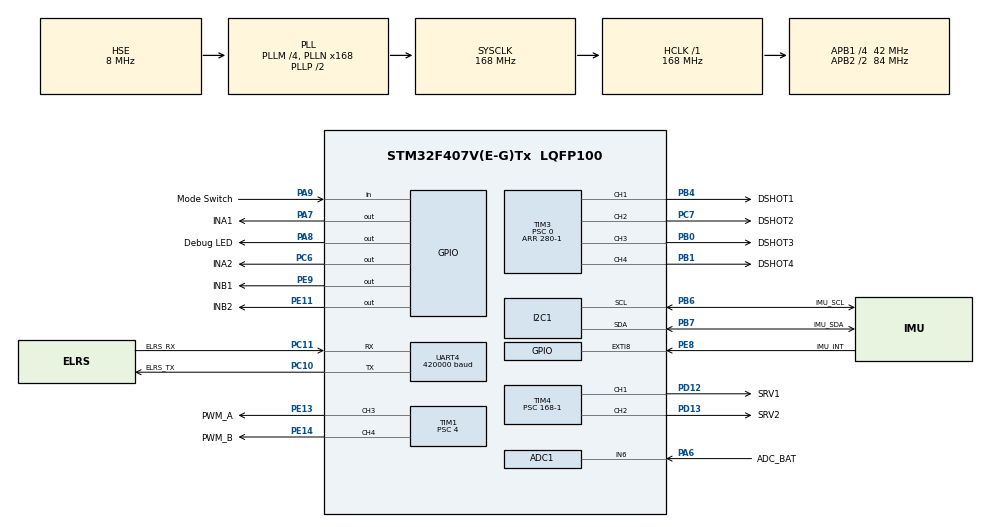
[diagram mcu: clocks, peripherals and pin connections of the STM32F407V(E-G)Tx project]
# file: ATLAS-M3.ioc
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ADC1.Channel-3\#ChannelRegularConversion=ADC_CHANNEL_6
ADC1.ClockPrescaler=ADC_CLOCK_SYNC_PCLK_DIV4
ADC1.ContinuousConvMode=ENABLE
ADC1.DMAContinuousRequests=ENABLE
ADC1.NbrOfConversion=1
ADC1.NbrOfConversionFlag=1
ADC1.Rank-3\#ChannelRegularConversion=1
ADC1.SamplingTime-3\#ChannelRegularConversion=ADC_SAMPLETIME_144CYCLES
ADC1.master=1
Dma.ADC1.0.Direction=DMA_PERIPH_TO_MEMORY
Dma.ADC1.0.FIFOMode=DMA_FIFOMODE_DISABLE
Dma.ADC1.0.Instance=DMA2_Stream0
Dma.ADC1.0.MemDataAlignment=DMA_MDATAALIGN_HALFWORD
Dma.ADC1.0.MemInc=DMA_MINC_ENABLE
Dma.ADC1.0.Mode=DMA_CIRCULAR
Dma.ADC1.0.PeriphDataAlignment=DMA_PDATAALIGN_HALFWORD
Dma.ADC1.0.PeriphInc=DMA_PINC_DISABLE
Dma.ADC1.0.Priority=DMA_PRIORITY_LOW
Dma.Request0=ADC1
Dma.Request1=TIM3_CH1/TRIG
Dma.Request2=TIM3_CH2
Dma.Request3=TIM3_CH3
Dma.Request4=TIM3_CH4/UP
Dma.TIM3_CH1/TRIG.1.Direction=DMA_MEMORY_TO_PERIPH
Dma.TIM3_CH1/TRIG.1.FIFOMode=DMA_FIFOMODE_DISABLE
Dma.TIM3_CH1/TRIG.1.Instance=DMA1_Stream4
Dma.TIM3_CH1/TRIG.1.MemDataAlignment=DMA_MDATAALIGN_HALFWORD
Dma.TIM3_CH1/TRIG.1.MemInc=DMA_MINC_ENABLE
Dma.TIM3_CH1/TRIG.1.Mode=DMA_NORMAL
Dma.TIM3_CH1/TRIG.1.PeriphDataAlignment=DMA_PDATAALIGN_HALFWORD
Dma.TIM3_CH1/TRIG.1.PeriphInc=DMA_PINC_DISABLE
Dma.TIM3_CH1/TRIG.1.Priority=DMA_PRIORITY_HIGH
Dma.TIM3_CH2.2.Direction=DMA_MEMORY_TO_PERIPH
Dma.TIM3_CH2.2.FIFOMode=DMA_FIFOMODE_DISABLE
Dma.TIM3_CH2.2.Instance=DMA1_Stream5
Dma.TIM3_CH2.2.MemDataAlignment=DMA_MDATAALIGN_HALFWORD
Dma.TIM3_CH2.2.MemInc=DMA_MINC_ENABLE
Dma.TIM3_CH2.2.Mode=DMA_NORMAL
Dma.TIM3_CH2.2.PeriphDataAlignment=DMA_PDATAALIGN_HALFWORD
Dma.TIM3_CH2.2.PeriphInc=DMA_PINC_DISABLE
Dma.TIM3_CH2.2.Priority=DMA_PRIORITY_HIGH
Dma.TIM3_CH3.3.Direction=DMA_MEMORY_TO_PERIPH
Dma.TIM3_CH3.3.FIFOMode=DMA_FIFOMODE_DISABLE
Dma.TIM3_CH3.3.Instance=DMA1_Stream7
Dma.TIM3_CH3.3.MemDataAlignment=DMA_MDATAALIGN_HALFWORD
Dma.TIM3_CH3.3.MemInc=DMA_MINC_ENABLE
Dma.TIM3_CH3.3.Mode=DMA_NORMAL
Dma.TIM3_CH3.3.PeriphDataAlignment=DMA_PDATAALIGN_HALFWORD
Dma.TIM3_CH3.3.PeriphInc=DMA_PINC_DISABLE
Dma.TIM3_CH3.3.Priority=DMA_PRIORITY_HIGH
Dma.TIM3_CH4/UP.4.Direction=DMA_MEMORY_TO_PERIPH
Dma.TIM3_CH4/UP.4.FIFOMode=DMA_FIFOMODE_DISABLE
Dma.TIM3_CH4/UP.4.Instance=DMA1_Stream2
Dma.TIM3_CH4/UP.4.MemDataAlignment=DMA_MDATAALIGN_HALFWORD
Dma.TIM3_CH4/UP.4.MemInc=DMA_MINC_ENABLE
Dma.TIM3_CH4/UP.4.Mode=DMA_NORMAL
Dma.TIM3_CH4/UP.4.PeriphDataAlignment=DMA_PDATAALIGN_HALFWORD
Dma.TIM3_CH4/UP.4.PeriphInc=DMA_PINC_DISABLE
Dma.TIM3_CH4/UP.4.Priority=DMA_PRIORITY_HIGH
I2C1.I2C_Mode=I2C_Standard
Mcu.Family=STM32F4
Mcu.Name=STM32F407V(E-G)Tx
Mcu.Package=LQFP100
NVIC.DMA1_Stream2_IRQn=true\:3\:0\:true\:false\:true\:false\:true\:true
NVIC.DMA1_Stream4_IRQn=true\:3\:0\:true\:false\:true\:false\:true\:true
NVIC.DMA1_Stream5_IRQn=true\:3\:0\:true\:false\:true\:false\:true\:true
NVIC.DMA1_Stream7_IRQn=true\:3\:0\:true\:false\:true\:false\:true\:true
NVIC.DMA2_Stream0_IRQn=true\:14\:0\:true\:false\:true\:false\:true\:true
NVIC.EXTI9_5_IRQn=true\:4\:0\:true\:false\:true\:true\:true\:true
NVIC.PriorityGroup=NVIC_PRIORITYGROUP_4
NVIC.RTC_WKUP_IRQn=true\:15\:0\:true\:false\:true\:true\:true\:true
NVIC.TIM3_IRQn=true\:0\:0\:false\:false\:true\:true\:true\:true
NVIC.UART4_IRQn=true\:1\:0\:true\:false\:true\:true\:true\:true
PA13.Signal=SYS_JTMS-SWDIO
PA14.Signal=SYS_JTCK-SWCLK
PA6.GPIO_Label=ADC_BAT
PA6.Signal=ADCx_IN6
PA7.GPIO_Label=INA1
PA7.GPIO_PuPd=GPIO_PULLDOWN
PA7.Signal=GPIO_Output
PA8.GPIO_Label=Debug LED
PA8.GPIO_PuPd=GPIO_PULLDOWN
PA8.Signal=GPIO_Output
PA9.GPIO_Label=Mode Switch
PA9.GPIO_PuPd=GPIO_PULLDOWN
PA9.Signal=GPIO_Input
PB0.GPIO_Label=DSHOT3
PB0.Signal=S_TIM3_CH3
PB1.GPIO_Label=DSHOT4
PB1.Signal=S_TIM3_CH4
PB4.GPIO_Label=DSHOT1
PB4.Signal=S_TIM3_CH1
PB6.GPIO_Label=IMU_SCL
PB6.Mode=I2C
PB6.Signal=I2C1_SCL
PB7.GPIO_Label=IMU_SDA
PB7.Mode=I2C
PB7.Signal=I2C1_SDA
PC10.GPIO_Label=ELRS_TX
PC10.Mode=Asynchronous
PC10.Signal=UART4_TX
PC11.GPIO_Label=ELRS_RX
PC11.Mode=Asynchronous
PC11.Signal=UART4_RX
PC14-OSC32_IN.Mode=LSE-External-Oscillator
PC14-OSC32_IN.Signal=RCC_OSC32_IN
PC15-OSC32_OUT.Mode=LSE-External-Oscillator
PC15-OSC32_OUT.Signal=RCC_OSC32_OUT
PC6.GPIO_Label=INA2
PC6.GPIO_PuPd=GPIO_PULLDOWN
PC6.Signal=GPIO_Output
PC7.GPIO_Label=DSHOT2
PC7.Signal=S_TIM3_CH2
PD12.GPIO_Label=SRV1
PD12.Signal=S_TIM4_CH1
PD13.GPIO_Label=SRV2
PD13.Signal=S_TIM4_CH2
PE11.GPIO_Label=INB2
PE11.GPIO_PuPd=GPIO_PULLDOWN
PE11.Signal=GPIO_Output
PE13.GPIO_Label=PWM_A
PE13.Signal=S_TIM1_CH3
PE14.GPIO_Label=PWM_B
PE14.Signal=S_TIM1_CH4
PE8.GPIO_Label=IMU_INT
PE8.GPIO_ModeDefaultEXTI=GPIO_MODE_IT_RISING
PE8.GPIO_PuPd=GPIO_PULLDOWN
PE8.Signal=GPXTI8
PE9.GPIO_Label=INB1
PE9.GPIO_PuPd=GPIO_PULLDOWN
PE9.Signal=GPIO_Output
PH0-OSC_IN.Mode=HSE-External-Oscillator
PH0-OSC_IN.Signal=RCC_OSC_IN
PH1-OSC_OUT.Mode=HSE-External-Oscillator
PH1-OSC_OUT.Signal=RCC_OSC_OUT
ProjectManager.HeapSize=0x200
ProjectManager.StackSize=0x400
ProjectManager.TargetToolchain=STM32CubeIDE
RCC.48MHZClocksFreq_Value=84000000
RCC.AHBFreq_Value=168000000
RCC.APB1CLKDivider=RCC_HCLK_DIV4
RCC.APB1Freq_Value=42000000
RCC.APB1TimFreq_Value=84000000
RCC.APB2CLKDivider=RCC_HCLK_DIV2
RCC.APB2Freq_Value=84000000
RCC.APB2TimFreq_Value=168000000
RCC.CortexFreq_Value=168000000
RCC.HCLKFreq_Value=168000000
RCC.HSE_VALUE=8000000
RCC.HSI_VALUE=16000000
RCC.PLLM=4
RCC.PLLN=168
RCC.PLLSourceVirtual=RCC_PLLSOURCE_HSE
RCC.RCC_RTC_Clock_Source=RCC_RTCCLKSOURCE_LSE
RCC.RCC_RTC_Clock_SourceVirtual=RCC_RTCCLKSOURCE_LSE
RCC.SYSCLKFreq_VALUE=168000000
RCC.SYSCLKSource=RCC_SYSCLKSOURCE_PLLCLK
RCC.VCOOutputFreq_Value=336000000
RTC.WakeUpCounter=10240
SH.ADCx_IN6.0=ADC1_IN6,IN6
SH.S_TIM1_CH3.0=TIM1_CH3,PWM Generation3 CH3
SH.S_TIM1_CH4.0=TIM1_CH4,PWM Generation4 CH4
SH.S_TIM3_CH1.0=TIM3_CH1,PWM Generation1 CH1
SH.S_TIM3_CH2.0=TIM3_CH2,PWM Generation2 CH2
SH.S_TIM3_CH3.0=TIM3_CH3,PWM Generation3 CH3
SH.S_TIM3_CH4.0=TIM3_CH4,PWM Generation4 CH4
SH.S_TIM4_CH1.0=TIM4_CH1,PWM Generation1 CH1
SH.S_TIM4_CH2.0=TIM4_CH2,PWM Generation2 CH2
TIM1.Channel-PWM\ Generation3\ CH3=TIM_CHANNEL_3
TIM1.Channel-PWM\ Generation4\ CH4=TIM_CHANNEL_4
TIM1.Period=1679
TIM1.Prescaler=4
TIM3.AutoReloadPreload=TIM_AUTORELOAD_PRELOAD_ENABLE
TIM3.Channel-PWM\ Generation1\ CH1=TIM_CHANNEL_1
TIM3.Channel-PWM\ Generation2\ CH2=TIM_CHANNEL_2
TIM3.Channel-PWM\ Generation3\ CH3=TIM_CHANNEL_3
TIM3.Channel-PWM\ Generation4\ CH4=TIM_CHANNEL_4
TIM3.Period=280-1
TIM3.Prescaler=0
TIM4.AutoReloadPreload=TIM_AUTORELOAD_PRELOAD_DISABLE
TIM4.Channel-PWM\ Generation1\ CH1=TIM_CHANNEL_1
TIM4.Channel-PWM\ Generation2\ CH2=TIM_CHANNEL_2
TIM4.Period=20000-1
TIM4.Prescaler=168-1
UART4.BaudRate=420000
UART4.VirtualMode=Asynchronous
VP_RTC_VS_RTC_Activate.Mode=RTC_Enabled
VP_RTC_VS_RTC_Calendar.Mode=RTC_Calendar
VP_RTC_VS_RTC_WakeUp_intern.Mode=WakeUp
VP_TIM1_VS_ClockSourceINT.Mode=Internal
VP_TIM3_VS_ClockSourceINT.Mode=Internal
VP_TIM4_VS_ClockSourceINT.Mode=Internal
board=custom

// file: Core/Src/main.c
/* USER CODE BEGIN Header */
/*	MCU reminders
cycle = 1 / Freq	-->	1 / 168MHz	=	5.95ns

									For 168MHz
Operation	|	Cycles	|	Time
Addition / Subtraction	|	1	|	5.95 ns
Multiplication (32-bit)	|	1	|	5.95 ns
Division (32-bit)		|2 – 12 |	12 – 71 ns
bit shifting			|	1	|	5.95ns
Array Access 			|	2	|	11.90 ns
for loop condition check|	1	|	5.95 ns

for faster dividion use bit shifting. this can work on any number divisible by 2^n. this only outputs integers
division = number>>9;	--> same as number/512

Every ISR must be calculated so that interrupt nesting is avoided. ISR's must be atleast 50% shorter than the interrupt itself.

 */

/* USER CODE END Header */
#include "main.h"

/* USER CODE BEGIN Includes */
// #include <> is used for system/language specific includes, while "" is used for project specific
#include <math.h>
#include "mpu6500.h"

/* USER CODE END Includes */

/* USER CODE BEGIN PTD */
typedef struct{//MPU struct
	float aX;		//Accelerometer. Units (g)gravity
	float aY;
	float aZ;

	float gX;		//Gyroscope. Units (dps)degrees per second
	float gY;
	float gZ;

}MPU_data;

typedef struct{ //UGV Controls
	//Joystick values must already be normalized from 0-8399

	int16_t leftMotor;
	int16_t rightMotor;

	int8_t leftMotor_Dir;	//+1 means Right turn; 	0 means Left turn and not moving
	int8_t rightMotor_Dir;	//+1 means Forward;    	0 means Backward and not moving

}UGV_controls;

typedef struct{	//Parameters to be sent by the ELRS
	int16_t batteryPercentage;

}ELRS_data;

/* USER CODE END PTD */

ADC_HandleTypeDef hadc1;
DMA_HandleTypeDef hdma_adc1;

I2C_HandleTypeDef hi2c1;

RTC_HandleTypeDef hrtc;

TIM_HandleTypeDef htim1;
TIM_HandleTypeDef htim3;
TIM_HandleTypeDef htim4;
DMA_HandleTypeDef hdma_tim3_ch1_trig;
DMA_HandleTypeDef hdma_tim3_ch2;
DMA_HandleTypeDef hdma_tim3_ch3;
DMA_HandleTypeDef hdma_tim3_ch4_up;

UART_HandleTypeDef huart4;

/* USER CODE BEGIN PV */

//-----------------------------------------------------Battery Monitor----------------------------------------------------
#define bufferSize 4096				// The amount of ADC reading to store

float maxVoltage = 3.029508;	//Max voltage of the Voltage divider
float minVoltage = 2.163934;

volatile uint16_t ADC_reading = 0;		//stores the ADC reading for battery percentage
volatile uint32_t ADCsum;				//stores the ISR ADC total

//This can change depending on the ADC reading of the Voltage Divider
uint16_t maxADC = 4095;
uint16_t minADC = 0;
uint16_t ADC_buffer[bufferSize];	//Array to temporarily store ADC readings

//----------------------------------------------------IMU-----------------------------------------------------
MPU_data MPU_Data;
HAL_StatusTypeDef status;

volatile uint8_t MPUstatus = 0;			//read MPU value when 1

uint8_t int_status;
int16_t accel_x, accel_y, accel_z;			//raw Place holders
int16_t gyro_x, gyro_y, gyro_z;

//---------------------------------------------------Camera------------------------------------------------------
uint8_t cameraAngle_X = 90;
uint8_t cameraAngle_Y = 90;
uint8_t cameraMove	= 0;		//Functions as a software interrupt. Only when this becomes 1 does the moveServo() run

//----------------------------------------------------UGV------------------------------------------------
#define maxUGV_Tick		1679			//set by the 20Khz counter
#define UGV_loopTime	0.005f			// loop time for the P (s). Must be same with Timer.
#define UGV_k 			30.0f			// P gain of the UGV

UGV_controls UGV_Controls;

uint16_t UGV_rightVelocity = 0;						//holder for current velocity is in pulse length for PWM
uint16_t UGV_leftVelocity = 0;

//------------------------------------------------UAV-------------------------------------------------
#define RAD_TO_DEG 			57.29577951f		// Equivalent to 180/pi
#define UAV_loopTime		1.0f/184.0f			// loop time for the PID (s). Must be same with MPU INT.
#define UAV_loopTime_INV 	184.0f				// Inverse of the loop time. specifically use this to save time when we want to divide a variable with the loopTime and since division uses 12 cycles while multiplication only uses 1
#define K_outer				1.0f				// Gain for the Outer PID
#define Kp_inner			0.1f				// P gain for the Inner PID
#define Ki_inner			0.1f				// I gain for the Inner PID
#define Kd_inner			0.001f				// D gain for the Inner PID
#define Lim					400.0f				// Summing limit of PID
#define Mass_Base			0.5f				// The weight of the drone without any load in (Kg)
#define normal_Hover  		1.0f/500.0f			// The hover value of the drone without any payload. Make sure it is inverse form so that the multiplication operation can be used
#define Rotmax 				1999.0f				// The max value the motors can have. This is derived from the DSHOT range which is 48-2047 --> 0 - 1999.
#define minTilt				5.0f				// degree
#define maxTilt				45.0f
#define maxYaw				200.0f				// degrees/second
#define minYaw				5.0f
#define filter_Alpha 		0.998f				// Alpha used for the complementary Filter
#define filter_Beta  		0.02f				// 1 - filter_Alpha
#define Calibration_Alpha 	0.005f				// Used for calibrationg hover point with payload

float rawThrust;	//Values stored directly from the ELRS
float rawRoll;
float rawPitch;
float rawYaw;

float Thrust;	//Must already be mapped from 0-1638
float Roll;		//Must already be mapped from -45deg to +45 deg. or whatever the max tilt of the drone is
float Pitch;	//Must already be mapped from -45deg to +45 deg. or whatever the max tilt of the drone is
float Yaw;		//Must already be mapped from -200deg/s to +200 deg/s. or whatever the max angular velocity of the drone is

float Filtered_Roll_Angle;
float Filtered_Pitch_Angle;

float Last_Filtered_Roll_Angle;
float Last_Filtered_Pitch_Angle;

float RollError;
float PitchError;
float YawError;

float last_gX;
float last_gY;
float last_gZ;

float Last_Roll_I;			//Previously calculated Roll Integral of the PID
float Last_Pitch_I;			//Previously calculated PitchIntegral of the PID
float Last_Yaw_I;			//Previously calculated Yaw of the PID

float Total_Roll;			//The Roll value after the PID
float Total_Pitch;			//The Pitch value after the PID
float Total_Yaw;			//The Yaw value after the PID
float Total_Thrust;

volatile uint8_t UAVloop 		 = 0;		//When PID loop is ongoing prevents the ELRS from getting a new data.

volatile uint8_t calibrationMode = 0;		//When this is 1, it tells the UAV to enter calibration mode
float Calibrated_Hover;		//Calibrated hover value of the drone with payload this should be within dshot value range
float massRatio;			//The ratio between the normal drone and with the payload

float Motor1;				//Front Right	||	CCW
float Motor2;				//Front Left	||	CW
float Motor3;				//Rear 	Left	||	CCW
float Motor4;				//Rear	Right	||	CW

float M1raw;				//stores the raw unmapped  speed of motors
float M2raw;
float M3raw;
float M4raw;

//-------------------------------------------------------DSHOT---------------------------------------------------------
#define DSHOT_1      210				// for dshot600 logic HIGH
#define DSHOT_0      105				// for dshot600 logic LOW
#define DSHOTmax	 1999.0f			// max dshot value
#define DSHOTcenter	 1000.0f			// the center of dshot mapped to the center of the joystick
#define DSHOT_BUFFER_SIZE 18 			// 16 bits + 2 zeros for the reset gap

uint16_t dshot_value;
uint16_t DSHOT_packet;

uint32_t dma_buffer[4][DSHOT_BUFFER_SIZE]; // [4 motors] [18 values each]
uint32_t timer_channels[4] = {TIM_CHANNEL_1, TIM_CHANNEL_2, TIM_CHANNEL_3, TIM_CHANNEL_4}; // Array to map our loop index (0-3) to the specific Timer Channels

//-----------------------------------------------ELRS & CRSF---------------------------------
#define ELRSMax 				 1811
#define ELRSMin 				 172
#define ELRS_lowerDeadZone 		 990
#define ELRS_higherDeadZone 	 993

ELRS_data ELRS_Data;

uint8_t ELRS_buffer[26];	//Received ELRS raw bits will be saved here
uint8_t ELRS_packet[26];	//Sent ELRS raw bits will be saved here

uint8_t rx_byte;              // Holds the single byte currently arriving
uint8_t rx_index = 0;         // Tracks where we are in the packet

uint16_t channels[16];		//Temporary stores channel values here when receiving
// Each payload channels can only have values ranging from 172 - 1811, which makes it a 1640 resolution

const uint8_t crsf_crc8_table[256] = {//Look up table for the CRC
    0x00, 0xD5, 0x7F, 0xAA, 0xFE, 0x2B, 0x81, 0x54, 0x29, 0xFC, 0x56, 0x83, 0xD7, 0x02, 0xA8, 0x7D,
    0x52, 0x87, 0x2D, 0xF8, 0xAC, 0x79, 0xD3, 0x06, 0x7B, 0xAE, 0x04, 0xD1, 0x85, 0x50, 0xFA, 0x2F,
    0xA4, 0x71, 0xDB, 0x0E, 0x5A, 0x8F, 0x25, 0xF0, 0x8D, 0x58, 0xF2, 0x27, 0x73, 0xA6, 0x0C, 0xD9,
    0xF6, 0x23, 0x89, 0x5C, 0x08, 0xDD, 0x77, 0xA2, 0xDF, 0x0A, 0xA0, 0x75, 0x21, 0xF4, 0x5E, 0x8B,
    0x4D, 0x98, 0x32, 0xE7, 0xB3, 0x66, 0xCC, 0x19, 0x64, 0xB1, 0x1B, 0xCE, 0x9A, 0x4F, 0xE5, 0x30,
    0x1F, 0xCA, 0x60, 0xB5, 0xE1, 0x34, 0x9E, 0x4B, 0x36, 0xE3, 0x49, 0x9C, 0xC8, 0x1D, 0xB7, 0x62,
    0xE9, 0x3C, 0x96, 0x43, 0x17, 0xC2, 0x68, 0xBD, 0xC0, 0x15, 0xBF, 0x6A, 0x3E, 0xEB, 0x41, 0x94,
    0xBB, 0x6E, 0xC4, 0x11, 0x45, 0x90, 0x3A, 0xEF, 0x92, 0x47, 0xED, 0x38, 0x6C, 0xB9, 0x13, 0xC6,
    0x9A, 0x4F, 0xE5, 0x30, 0x64, 0xB1, 0x1B, 0xCE, 0xB3, 0x66, 0xCC, 0x19, 0x4D, 0x98, 0x32, 0xE7,
    0xC8, 0x1D, 0xB7, 0x62, 0x36, 0xE3, 0x49, 0x9C, 0xE1, 0x34, 0x9E, 0x4B, 0x1F, 0xCA, 0x60, 0xB5,
    0x3E, 0xEB, 0x41, 0x94, 0xC0, 0x15, 0xBF, 0x6A, 0x17, 0xC2, 0x68, 0xBD, 0xE9, 0x3C, 0x96, 0x43,
    0x6C, 0xB9, 0x13, 0xC6, 0x92, 0x47, 0xED, 0x38, 0x45, 0x90, 0x3A, 0xEF, 0xBB, 0x6E, 0xC4, 0x11,
    0xD7, 0x02, 0xA8, 0x7D, 0x29, 0xFC, 0x56, 0x83, 0xFE, 0x2B, 0x81, 0x54, 0x00, 0xD5, 0x7F, 0xAA,
    0x85, 0x50, 0xFA, 0x2F, 0x7B, 0xAE, 0x04, 0xD1, 0xDB, 0x0E, 0xA4, 0x71, 0x25, 0xF0, 0x5A, 0x8F,
    0x73, 0xA6, 0x0C, 0xD9, 0x8D, 0x58, 0xF2, 0x27, 0x5A, 0x8F, 0x25, 0xF0, 0xA4, 0x71, 0xDB, 0x0E,
    0x21, 0xF4, 0x5E, 0x8B, 0xDF, 0x0A, 0xA0, 0x75, 0x08, 0xDD, 0x77, 0xA2, 0xF6, 0x23, 0x89, 0x5C
};

//---------------------------------------------------------------------Modular settings------------------------------------------------
//All these Variables are changed only depending on the modular configuration
uint8_t UV_MODE = 1;	//0=UGV ||	1=UAV
/*
 * This is configured inside the MX_GPIO_Init();
 *
 * for testing make sure to disable the algorithm inside MX_GPIO_Init(), so it doesnt pull the mode to 0 without a switch
 */

uint8_t stopMotor = 0; 			//when this is 1 it sends 0 to ESC via DSHOT so the BLDC doesnt spin.

uint8_t errorMax = 10;
uint32_t error = 0;				//Each number corresponds to different errors

/* USER CODE END PV */

void SystemClock_Config(void);
static void MX_GPIO_Init(void);
static void MX_DMA_Init(void);
static void MX_I2C1_Init(void);
static void MX_UART4_Init(void);
static void MX_TIM3_Init(void);
static void MX_ADC1_Init(void);
static void MX_TIM1_Init(void);
static void MX_RTC_Init(void);
static void MX_TIM4_Init(void);
/* USER CODE BEGIN PFP */
float map(float x, float in_min, float in_max, float out_min, float out_max);
void readBattery();

void readMPU();

void moveServo();
void setServoAngle(TIM_HandleTypeDef *htim, uint32_t channel, uint8_t angle);

void UGV_setSpeed(TIM_HandleTypeDef *htim, uint32_t channel, int16_t *V_target, uint16_t *V_current);
void UGV_setDirection(GPIO_TypeDef* Port_A, uint16_t Pin_A, GPIO_TypeDef* Port_B, uint16_t Pin_B, int8_t *direction);

void CRSF_Parser(uint8_t* packet, ELRS_data* input);
void extractELRS(uint8_t* buf, uint16_t* ch);
uint8_t bitMask(uint16_t ch1);
uint8_t crsf_crc8(uint8_t *ptr, uint8_t len);

void UAV_convertTilt(float rawAxis, float *Axis);
void UAV_convertYaw(float rawAxis, float *Axis);
void complementaryFilter();
void UAV_error();
void UAV_PID(float *Total, float error, float *last_I, float gyro, float *last_gyro);
void UAV_normalizeMotor();
void UAV_convertThrust();

void DSHOT_Fire();
void DSHOT_PreparePacket(uint16_t throttle, uint8_t motorNumber, uint8_t stop_button, uint8_t request_telemetry);

/* USER CODE END PFP */

int main(void)
{

  /* MCU Configuration--------------------------------------------------------*/

  /* Reset of all peripherals, Initializes the Flash interface and the Systick. */
  HAL_Init();

  /* Configure the system clock */
  SystemClock_Config();

  /* Initialize all configured peripherals */
  MX_GPIO_Init();
  MX_DMA_Init();
  MX_I2C1_Init();
  MX_UART4_Init();
  MX_TIM3_Init();
  MX_ADC1_Init();
  MX_TIM1_Init();
  MX_RTC_Init();
  MX_TIM4_Init();
  /* USER CODE BEGIN 2 */

  HAL_ADC_Start_DMA(&hadc1, (uint32_t*)&ADC_buffer, bufferSize);	//Start the ADC and tell the DMA to where to store the data

  HAL_RTCEx_SetWakeUpTimer_IT(&hrtc, 10240, RTC_WAKEUPCLOCK_RTCCLK_DIV16);	//Start the LSE Timer

  //Starts timer for motor driver
  HAL_TIM_PWM_Start(&htim1, TIM_CHANNEL_3);
  HAL_TIM_PWM_Start(&htim1, TIM_CHANNEL_4);

  //Starts timer for servo
  HAL_TIM_PWM_Start(&htim4, TIM_CHANNEL_1);
  HAL_TIM_PWM_Start(&htim4, TIM_CHANNEL_2);

  //Start UART for ELRS		||	remove this when ELRS is not connected to avoid unintentional ISR firing
  //HAL_UART_Receive_IT(&huart4, &rx_byte, 1);

  if (UV_MODE){//Only enable this when mode is UAV
	  // when connecting to STM32 make sure to use the 3v3 source so it minimizes the noise
	  //disable this when MPU is disconnected because Error_Handler() causes a loop.
	  status = MPU6500_Init();	//Initialize MPU6500
	  if(status != HAL_OK){
		  error = 1;
	  }

	  status = MPU6500_EnableDataReadyInterrupts();	//Enable Interrupt pin
	  if(status != HAL_OK){
		  error = 2;
	  }

  }

  /* USER CODE END 2 */

  /* Infinite loop */
  while (1) {

    /* USER CODE BEGIN 3 */

	  switch (UV_MODE){
		  case 0 :	//UGV Mode-------------------------------------------------------------------------------
			  moveServo();

			  readBattery();

			  CRSF_Parser(ELRS_packet, &ELRS_Data);

			  break;

		  case 1 :	//UAV Mode------------------------------------------------------------------------------
			  if (MPUstatus){
				  UAVloop = 1;		//Makes sure the ELRS doesnt get new data
				  readMPU();

				  UAV_convertTilt(rawRoll, &Roll);
				  UAV_convertTilt(rawPitch, &Pitch);
				  UAV_convertYaw(rawYaw, &Yaw);
				  UAV_convertThrust();

				  complementaryFilter();

				  UAV_error();
				  UAV_PID(&Total_Roll, RollError, &Last_Roll_I, MPU_Data.gX, &last_gX);		//Roll 	PID
				  UAV_PID(&Total_Pitch, PitchError, &Last_Pitch_I, MPU_Data.gY, &last_gY); 	//Pitch PID
				  UAV_PID(&Total_Yaw, YawError, &Last_Yaw_I, MPU_Data.gZ, &last_gZ);		//Yaw	PID
				  UAV_normalizeMotor();														//Calculate raw thrust for each motor

				  //Convert motor values to DSHOT
				  DSHOT_PreparePacket(Motor1, 0, 0, 0);
				  DSHOT_PreparePacket(Motor2, 1, 0, 0);
				  DSHOT_PreparePacket(Motor3, 2, 0, 0);
				  DSHOT_PreparePacket(Motor4, 3, 0, 0);

				  DSHOT_Fire();		//Fire the DSHOT to the ESC

				  UAVloop = 0;		//Allows the ELRS to get new data
				  //until here taked ~370 to 470 microseconds
			  }

			  while (calibrationMode){//	While calibration mode is turned on by the ELRS

				  if (rawThrust >= ELRS_higherDeadZone){
					  Thrust = map(rawThrust, ELRS_higherDeadZone, ELRSMax, 1001, DSHOTmax);
				  }

				  else if (rawThrust <= ELRS_lowerDeadZone){
					  Thrust = map(rawThrust, ELRSMin, ELRS_lowerDeadZone, 0, DSHOTcenter - 1);
				  }

				  else{
					  Thrust = DSHOTcenter;
				  }

				  Calibrated_Hover = Calibrated_Hover + Calibration_Alpha * (Thrust - Calibrated_Hover);

				  //Convert motor values to DSHOT
				  DSHOT_PreparePacket(Calibrated_Hover, 0, 0, 0);
				  DSHOT_PreparePacket(Calibrated_Hover, 1, 0, 0);
				  DSHOT_PreparePacket(Calibrated_Hover, 2, 0, 0);
				  DSHOT_PreparePacket(Calibrated_Hover, 3, 0, 0);

				  DSHOT_Fire();		//Fire the DSHOT to the ESC

				  massRatio = Calibrated_Hover * normal_Hover;	//Remove this for initial calibration of unloaded drone
			  }

			  moveServo();

			  readBattery();

			 // CRSF_Parser(ELRS_packet, &ELRS_Data);

			  break;

		  default:	//Error
			  error = 6;
			  Error_Handler();
			  break;
	  }
  }
  /* USER CODE END 3 */
}

void SystemClock_Config(void)
{
  RCC_OscInitTypeDef RCC_OscInitStruct = {0};
  RCC_ClkInitTypeDef RCC_ClkInitStruct = {0};

  /** Configure the main internal regulator output voltage
  */
  __HAL_RCC_PWR_CLK_ENABLE();
  __HAL_PWR_VOLTAGESCALING_CONFIG(PWR_REGULATOR_VOLTAGE_SCALE1);

  /** Initializes the RCC Oscillators according to the specified parameters
  * in the RCC_OscInitTypeDef structure.
  */
  RCC_OscInitStruct.OscillatorType = RCC_OSCILLATORTYPE_HSE|RCC_OSCILLATORTYPE_LSE;
  RCC_OscInitStruct.HSEState = RCC_HSE_ON;
  RCC_OscInitStruct.LSEState = RCC_LSE_ON;
  RCC_OscInitStruct.PLL.PLLState = RCC_PLL_ON;
  RCC_OscInitStruct.PLL.PLLSource = RCC_PLLSOURCE_HSE;
  RCC_OscInitStruct.PLL.PLLM = 4;
  RCC_OscInitStruct.PLL.PLLN = 168;
  RCC_OscInitStruct.PLL.PLLP = RCC_PLLP_DIV2;
  RCC_OscInitStruct.PLL.PLLQ = 4;
  if (HAL_RCC_OscConfig(&RCC_OscInitStruct) != HAL_OK)
  {
    Error_Handler();
  }

  /** Initializes the CPU, AHB and APB buses clocks
  */
  RCC_ClkInitStruct.ClockType = RCC_CLOCKTYPE_HCLK|RCC_CLOCKTYPE_SYSCLK
                              |RCC_CLOCKTYPE_PCLK1|RCC_CLOCKTYPE_PCLK2;
  RCC_ClkInitStruct.SYSCLKSource = RCC_SYSCLKSOURCE_PLLCLK;
  RCC_ClkInitStruct.AHBCLKDivider = RCC_SYSCLK_DIV1;
  RCC_ClkInitStruct.APB1CLKDivider = RCC_HCLK_DIV4;
  RCC_ClkInitStruct.APB2CLKDivider = RCC_HCLK_DIV2;

  if (HAL_RCC_ClockConfig(&RCC_ClkInitStruct, FLASH_LATENCY_5) != HAL_OK)
  {
    Error_Handler();
  }
}

static void MX_ADC1_Init(void)
{

  ADC_ChannelConfTypeDef sConfig = {0};

  /* USER CODE BEGIN ADC1_Init 1 */
/* The hadc1.Init.ClockPrescaler = ADC_CLOCK_SYNC_PCLK_DIV6;
 * -> this determines the sampling rate where the APB2 is divided by the prescaler
 *
 *  sConfig.SamplingTime = ADC_SAMPLETIME_15CYCLES;
 *  -> this determins how many cycles the ADC looks before storeing the data for more stable reading
 */

  /* USER CODE END ADC1_Init 1 */

  /** Configure the global features of the ADC (Clock, Resolution, Data Alignment and number of conversion)
  */
  hadc1.Instance = ADC1;
  hadc1.Init.ClockPrescaler = ADC_CLOCK_SYNC_PCLK_DIV4;
  hadc1.Init.Resolution = ADC_RESOLUTION_12B;
  hadc1.Init.ScanConvMode = DISABLE;
  hadc1.Init.ContinuousConvMode = ENABLE;
  hadc1.Init.DiscontinuousConvMode = DISABLE;
  hadc1.Init.ExternalTrigConvEdge = ADC_EXTERNALTRIGCONVEDGE_NONE;
  hadc1.Init.ExternalTrigConv = ADC_SOFTWARE_START;
  hadc1.Init.DataAlign = ADC_DATAALIGN_RIGHT;
  hadc1.Init.NbrOfConversion = 1;
  hadc1.Init.DMAContinuousRequests = ENABLE;
  hadc1.Init.EOCSelection = ADC_EOC_SINGLE_CONV;
  if (HAL_ADC_Init(&hadc1) != HAL_OK)
  {
    Error_Handler();
  }

  /** Configure for the selected ADC regular channel its corresponding rank in the sequencer and its sample time.
  */
  sConfig.Channel = ADC_CHANNEL_6;
  sConfig.Rank = 1;
  sConfig.SamplingTime = ADC_SAMPLETIME_144CYCLES;
  if (HAL_ADC_ConfigChannel(&hadc1, &sConfig) != HAL_OK)
  {
    Error_Handler();
  }

}

static void MX_I2C1_Init(void)
{

  hi2c1.Instance = I2C1;
  hi2c1.Init.ClockSpeed = 100000;
  hi2c1.Init.DutyCycle = I2C_DUTYCYCLE_2;
  hi2c1.Init.OwnAddress1 = 0;
  hi2c1.Init.AddressingMode = I2C_ADDRESSINGMODE_7BIT;
  hi2c1.Init.DualAddressMode = I2C_DUALADDRESS_DISABLE;
  hi2c1.Init.OwnAddress2 = 0;
  hi2c1.Init.GeneralCallMode = I2C_GENERALCALL_DISABLE;
  hi2c1.Init.NoStretchMode = I2C_NOSTRETCH_DISABLE;
  if (HAL_I2C_Init(&hi2c1) != HAL_OK)
  {
    Error_Handler();
  }

}

static void MX_RTC_Init(void)
{

  RTC_TimeTypeDef sTime = {0};
  RTC_DateTypeDef sDate = {0};

  /** Initialize RTC Only
  */
  hrtc.Instance = RTC;
  hrtc.Init.HourFormat = RTC_HOURFORMAT_24;
  hrtc.Init.AsynchPrediv = 127;
  hrtc.Init.SynchPrediv = 255;
  hrtc.Init.OutPut = RTC_OUTPUT_DISABLE;
  hrtc.Init.OutPutPolarity = RTC_OUTPUT_POLARITY_HIGH;
  hrtc.Init.OutPutType = RTC_OUTPUT_TYPE_OPENDRAIN;
  if (HAL_RTC_Init(&hrtc) != HAL_OK)
  {
    Error_Handler();
  }

  /** Initialize RTC and set the Time and Date
  */
  sTime.Hours = 0x0;
  sTime.Minutes = 0x0;
  sTime.Seconds = 0x0;
  sTime.DayLightSaving = RTC_DAYLIGHTSAVING_NONE;
  sTime.StoreOperation = RTC_STOREOPERATION_RESET;
  if (HAL_RTC_SetTime(&hrtc, &sTime, RTC_FORMAT_BCD) != HAL_OK)
  {
    Error_Handler();
  }
  sDate.WeekDay = RTC_WEEKDAY_MONDAY;
  sDate.Month = RTC_MONTH_JANUARY;
  sDate.Date = 0x1;
  sDate.Year = 0x0;

  if (HAL_RTC_SetDate(&hrtc, &sDate, RTC_FORMAT_BCD) != HAL_OK)
  {
    Error_Handler();
  }

  /** Enable the WakeUp
  */
  if (HAL_RTCEx_SetWakeUpTimer_IT(&hrtc, 10240, RTC_WAKEUPCLOCK_RTCCLK_DIV16) != HAL_OK)
  {
    Error_Handler();
  }

}

static void MX_TIM1_Init(void)
{

  TIM_ClockConfigTypeDef sClockSourceConfig = {0};
  TIM_MasterConfigTypeDef sMasterConfig = {0};
  TIM_OC_InitTypeDef sConfigOC = {0};
  TIM_BreakDeadTimeConfigTypeDef sBreakDeadTimeConfig = {0};

  htim1.Instance = TIM1;
  htim1.Init.Prescaler = 4;
  htim1.Init.CounterMode = TIM_COUNTERMODE_UP;
  htim1.Init.Period = 1679;
  htim1.Init.ClockDivision = TIM_CLOCKDIVISION_DIV1;
  htim1.Init.RepetitionCounter = 0;
  htim1.Init.AutoReloadPreload = TIM_AUTORELOAD_PRELOAD_DISABLE;
  if (HAL_TIM_Base_Init(&htim1) != HAL_OK)
  {
    Error_Handler();
  }
  sClockSourceConfig.ClockSource = TIM_CLOCKSOURCE_INTERNAL;
  if (HAL_TIM_ConfigClockSource(&htim1, &sClockSourceConfig) != HAL_OK)
  {
    Error_Handler();
  }
  if (HAL_TIM_PWM_Init(&htim1) != HAL_OK)
  {
    Error_Handler();
  }
  sMasterConfig.MasterOutputTrigger = TIM_TRGO_RESET;
  sMasterConfig.MasterSlaveMode = TIM_MASTERSLAVEMODE_DISABLE;
  if (HAL_TIMEx_MasterConfigSynchronization(&htim1, &sMasterConfig) != HAL_OK)
  {
    Error_Handler();
  }
  sConfigOC.OCMode = TIM_OCMODE_PWM1;
  sConfigOC.Pulse = 0;
  sConfigOC.OCPolarity = TIM_OCPOLARITY_HIGH;
  sConfigOC.OCNPolarity = TIM_OCNPOLARITY_HIGH;
  sConfigOC.OCFastMode = TIM_OCFAST_DISABLE;
  sConfigOC.OCIdleState = TIM_OCIDLESTATE_RESET;
  sConfigOC.OCNIdleState = TIM_OCNIDLESTATE_RESET;
  if (HAL_TIM_PWM_ConfigChannel(&htim1, &sConfigOC, TIM_CHANNEL_3) != HAL_OK)
  {
    Error_Handler();
  }
  if (HAL_TIM_PWM_ConfigChannel(&htim1, &sConfigOC, TIM_CHANNEL_4) != HAL_OK)
  {
    Error_Handler();
  }
  sBreakDeadTimeConfig.OffStateRunMode = TIM_OSSR_DISABLE;
  sBreakDeadTimeConfig.OffStateIDLEMode = TIM_OSSI_DISABLE;
  sBreakDeadTimeConfig.LockLevel = TIM_LOCKLEVEL_OFF;
  sBreakDeadTimeConfig.DeadTime = 0;
  sBreakDeadTimeConfig.BreakState = TIM_BREAK_DISABLE;
  sBreakDeadTimeConfig.BreakPolarity = TIM_BREAKPOLARITY_HIGH;
  sBreakDeadTimeConfig.AutomaticOutput = TIM_AUTOMATICOUTPUT_DISABLE;
  if (HAL_TIMEx_ConfigBreakDeadTime(&htim1, &sBreakDeadTimeConfig) != HAL_OK)
  {
    Error_Handler();
  }
  HAL_TIM_MspPostInit(&htim1);

}

static void MX_TIM3_Init(void)
{

  TIM_ClockConfigTypeDef sClockSourceConfig = {0};
  TIM_MasterConfigTypeDef sMasterConfig = {0};
  TIM_OC_InitTypeDef sConfigOC = {0};

  htim3.Instance = TIM3;
  htim3.Init.Prescaler = 0;
  htim3.Init.CounterMode = TIM_COUNTERMODE_UP;
  htim3.Init.Period = 280-1;
  htim3.Init.ClockDivision = TIM_CLOCKDIVISION_DIV1;
  htim3.Init.AutoReloadPreload = TIM_AUTORELOAD_PRELOAD_ENABLE;
  if (HAL_TIM_Base_Init(&htim3) != HAL_OK)
  {
    Error_Handler();
  }
  sClockSourceConfig.ClockSource = TIM_CLOCKSOURCE_INTERNAL;
  if (HAL_TIM_ConfigClockSource(&htim3, &sClockSourceConfig) != HAL_OK)
  {
    Error_Handler();
  }
  if (HAL_TIM_PWM_Init(&htim3) != HAL_OK)
  {
    Error_Handler();
  }
  sMasterConfig.MasterOutputTrigger = TIM_TRGO_RESET;
  sMasterConfig.MasterSlaveMode = TIM_MASTERSLAVEMODE_DISABLE;
  if (HAL_TIMEx_MasterConfigSynchronization(&htim3, &sMasterConfig) != HAL_OK)
  {
    Error_Handler();
  }
  sConfigOC.OCMode = TIM_OCMODE_PWM1;
  sConfigOC.Pulse = 0;
  sConfigOC.OCPolarity = TIM_OCPOLARITY_HIGH;
  sConfigOC.OCFastMode = TIM_OCFAST_DISABLE;
  if (HAL_TIM_PWM_ConfigChannel(&htim3, &sConfigOC, TIM_CHANNEL_1) != HAL_OK)
  {
    Error_Handler();
  }
  if (HAL_TIM_PWM_ConfigChannel(&htim3, &sConfigOC, TIM_CHANNEL_2) != HAL_OK)
  {
    Error_Handler();
  }
  if (HAL_TIM_PWM_ConfigChannel(&htim3, &sConfigOC, TIM_CHANNEL_3) != HAL_OK)
  {
    Error_Handler();
  }
  if (HAL_TIM_PWM_ConfigChannel(&htim3, &sConfigOC, TIM_CHANNEL_4) != HAL_OK)
  {
    Error_Handler();
  }
  HAL_TIM_MspPostInit(&htim3);

}

static void MX_TIM4_Init(void)
{

  TIM_ClockConfigTypeDef sClockSourceConfig = {0};
  TIM_MasterConfigTypeDef sMasterConfig = {0};
  TIM_OC_InitTypeDef sConfigOC = {0};

  htim4.Instance = TIM4;
  htim4.Init.Prescaler = 168-1;
  htim4.Init.CounterMode = TIM_COUNTERMODE_UP;
  htim4.Init.Period = 20000-1;
  htim4.Init.ClockDivision = TIM_CLOCKDIVISION_DIV1;
  htim4.Init.AutoReloadPreload = TIM_AUTORELOAD_PRELOAD_DISABLE;
  if (HAL_TIM_Base_Init(&htim4) != HAL_OK)
  {
    Error_Handler();
  }
  sClockSourceConfig.ClockSource = TIM_CLOCKSOURCE_INTERNAL;
  if (HAL_TIM_ConfigClockSource(&htim4, &sClockSourceConfig) != HAL_OK)
  {
    Error_Handler();
  }
  if (HAL_TIM_PWM_Init(&htim4) != HAL_OK)
  {
    Error_Handler();
  }
  sMasterConfig.MasterOutputTrigger = TIM_TRGO_RESET;
  sMasterConfig.MasterSlaveMode = TIM_MASTERSLAVEMODE_DISABLE;
  if (HAL_TIMEx_MasterConfigSynchronization(&htim4, &sMasterConfig) != HAL_OK)
  {
    Error_Handler();
  }
  sConfigOC.OCMode = TIM_OCMODE_PWM1;
  sConfigOC.Pulse = 0;
  sConfigOC.OCPolarity = TIM_OCPOLARITY_HIGH;
  sConfigOC.OCFastMode = TIM_OCFAST_DISABLE;
  if (HAL_TIM_PWM_ConfigChannel(&htim4, &sConfigOC, TIM_CHANNEL_1) != HAL_OK)
  {
    Error_Handler();
  }
  if (HAL_TIM_PWM_ConfigChannel(&htim4, &sConfigOC, TIM_CHANNEL_2) != HAL_OK)
  {
    Error_Handler();
  }
  HAL_TIM_MspPostInit(&htim4);

}

static void MX_UART4_Init(void)
{

  huart4.Instance = UART4;
  huart4.Init.BaudRate = 420000;
  huart4.Init.WordLength = UART_WORDLENGTH_8B;
  huart4.Init.StopBits = UART_STOPBITS_1;
  huart4.Init.Parity = UART_PARITY_NONE;
  huart4.Init.Mode = UART_MODE_TX_RX;
  huart4.Init.HwFlowCtl = UART_HWCONTROL_NONE;
  huart4.Init.OverSampling = UART_OVERSAMPLING_16;
  if (HAL_UART_Init(&huart4) != HAL_OK)
  {
    Error_Handler();
  }

}

static void MX_DMA_Init(void)
{

  /* DMA controller clock enable */
  __HAL_RCC_DMA2_CLK_ENABLE();
  __HAL_RCC_DMA1_CLK_ENABLE();

  /* DMA interrupt init */
  /* DMA1_Stream2_IRQn interrupt configuration */
  HAL_NVIC_SetPriority(DMA1_Stream2_IRQn, 3, 0);
  HAL_NVIC_EnableIRQ(DMA1_Stream2_IRQn);
  /* DMA1_Stream4_IRQn interrupt configuration */
  HAL_NVIC_SetPriority(DMA1_Stream4_IRQn, 3, 0);
  HAL_NVIC_EnableIRQ(DMA1_Stream4_IRQn);
  /* DMA1_Stream5_IRQn interrupt configuration */
  HAL_NVIC_SetPriority(DMA1_Stream5_IRQn, 3, 0);
  HAL_NVIC_EnableIRQ(DMA1_Stream5_IRQn);
  /* DMA1_Stream7_IRQn interrupt configuration */
  HAL_NVIC_SetPriority(DMA1_Stream7_IRQn, 3, 0);
  HAL_NVIC_EnableIRQ(DMA1_Stream7_IRQn);
  /* DMA2_Stream0_IRQn interrupt configuration */
  HAL_NVIC_SetPriority(DMA2_Stream0_IRQn, 14, 0);
  HAL_NVIC_EnableIRQ(DMA2_Stream0_IRQn);

}

static void MX_GPIO_Init(void)
{
  GPIO_InitTypeDef GPIO_InitStruct = {0};

  /* GPIO Ports Clock Enable */
  __HAL_RCC_GPIOC_CLK_ENABLE();
  __HAL_RCC_GPIOH_CLK_ENABLE();
  __HAL_RCC_GPIOA_CLK_ENABLE();
  __HAL_RCC_GPIOB_CLK_ENABLE();
  __HAL_RCC_GPIOE_CLK_ENABLE();
  __HAL_RCC_GPIOD_CLK_ENABLE();

  /*Configure GPIO pin Output Level */
  HAL_GPIO_WritePin(GPIOA, INA1_Pin|Debug_LED_Pin, GPIO_PIN_RESET);

  /*Configure GPIO pin Output Level */
  HAL_GPIO_WritePin(GPIOE, INB1_Pin|INB2_Pin, GPIO_PIN_RESET);

  /*Configure GPIO pin Output Level */
  HAL_GPIO_WritePin(INA2_GPIO_Port, INA2_Pin, GPIO_PIN_RESET);

  /*Configure GPIO pins : INA1_Pin Debug_LED_Pin */
  GPIO_InitStruct.Pin = INA1_Pin|Debug_LED_Pin;
  GPIO_InitStruct.Mode = GPIO_MODE_OUTPUT_PP;
  GPIO_InitStruct.Pull = GPIO_PULLDOWN;
  GPIO_InitStruct.Speed = GPIO_SPEED_FREQ_LOW;
  HAL_GPIO_Init(GPIOA, &GPIO_InitStruct);

  /*Configure GPIO pin : IMU_INT_Pin */
  GPIO_InitStruct.Pin = IMU_INT_Pin;
  GPIO_InitStruct.Mode = GPIO_MODE_IT_RISING;
  GPIO_InitStruct.Pull = GPIO_PULLDOWN;
  HAL_GPIO_Init(IMU_INT_GPIO_Port, &GPIO_InitStruct);

  /*Configure GPIO pins : INB1_Pin INB2_Pin */
  GPIO_InitStruct.Pin = INB1_Pin|INB2_Pin;
  GPIO_InitStruct.Mode = GPIO_MODE_OUTPUT_PP;
  GPIO_InitStruct.Pull = GPIO_PULLDOWN;
  GPIO_InitStruct.Speed = GPIO_SPEED_FREQ_LOW;
  HAL_GPIO_Init(GPIOE, &GPIO_InitStruct);

  /*Configure GPIO pin : INA2_Pin */
  GPIO_InitStruct.Pin = INA2_Pin;
  GPIO_InitStruct.Mode = GPIO_MODE_OUTPUT_PP;
  GPIO_InitStruct.Pull = GPIO_PULLDOWN;
  GPIO_InitStruct.Speed = GPIO_SPEED_FREQ_LOW;
  HAL_GPIO_Init(INA2_GPIO_Port, &GPIO_InitStruct);

  /*Configure GPIO pin : Mode_Switch_Pin */
  GPIO_InitStruct.Pin = Mode_Switch_Pin;
  GPIO_InitStruct.Mode = GPIO_MODE_INPUT;
  GPIO_InitStruct.Pull = GPIO_PULLDOWN;
  HAL_GPIO_Init(Mode_Switch_GPIO_Port, &GPIO_InitStruct);

  /* EXTI interrupt init*/
  HAL_NVIC_SetPriority(EXTI9_5_IRQn, 4, 0);
  HAL_NVIC_EnableIRQ(EXTI9_5_IRQn);

  /* USER CODE BEGIN MX_GPIO_Init_2 */
  // Must configure the MODE after the PIN initialization

  /*
  if (HAL_GPIO_ReadPin(Mode_Switch_GPIO_Port, Mode_Switch_Pin) == GPIO_PIN_SET) {
        MODE = 1;
    } else { MODE = 0;    }
*/
  /* USER CODE END MX_GPIO_Init_2 */
}

/* USER CODE BEGIN 4 */

float map(float x, float in_min, float in_max, float out_min, float out_max) {
    // Prevent Division by Zero: if the input range is nothing, return the lower output bound
    if (in_max == in_min) {return out_min;}

    // Standard linear interpolation formula:
    // (x - in_min) / (in_max - in_min) calculates the "percentage" across the input scale
    // Then we multiply that percentage by the output range and add the offset
    return (x - in_min) * (out_max - out_min) / (in_max - in_min) + out_min;
}

void moveServo(){// move the servo using received angle

	if(!cameraMove)return;

	cameraMove = 0;

	setServoAngle(&htim4, TIM_CHANNEL_1, cameraAngle_X);
	setServoAngle(&htim4, TIM_CHANNEL_2, cameraAngle_Y);
}

void setServoAngle(TIM_HandleTypeDef *htim, uint32_t channel, uint8_t angle){//	sets the servo angle via timer PWM
	/*Convert servo pulse time to timer counts
	 *MCU Frequency = 168MHz
	 *Prescaler = 167
	 *Clock tick = 168,000,000 / 167 + 1
	 *Clock tick = 1uS
	 *			From Datasheet
	 *Minimum Counts =  300uS/1uS	  = 300		//0   deg
	 *Maximum Counts =  1,300uS/1uS	  = 1300	//180 deg
	*/

	//Map angle (0-180) via linear interpolation
	uint32_t pulse_length = 300 + (angle * (1300-300)/180);

	__HAL_TIM_SET_COMPARE(htim,channel,pulse_length);	//write duty cycle to PWM
}

void readMPU(){	//	reads the MPU values using the library
	//This whole function takes ~350 - 450us

	MPUstatus = 0;
	if(calibrationMode){// Skip the MPU when in calibration Mode
		return;
	}

	//Acknowledge that the INP pin was received.
	HAL_I2C_Mem_Read(&hi2c1, (0x68 << 1), 0x3A, I2C_MEMADD_SIZE_8BIT, &int_status, 1, 100);	//This  is where 97% of the fuction is stalling

	// Read raw sensor data
	status = MPU6500_ReadAccel(&accel_x, &accel_y, &accel_z);
	if(status != HAL_OK){
		error=4;
		return;
		}

	status = MPU6500_ReadGyro(&gyro_x, &gyro_y, &gyro_z);
	if(status != HAL_OK){
		error=5;
		return;
		}

	// Convert raw data to physical units
	// For ±8g range: 1g = 4096 LSB
	MPU_Data.aX = accel_x / 4096.0f;
	MPU_Data.aY = accel_y / 4096.0f;
	MPU_Data.aZ = accel_z / 4096.0f;

	// For ±2000°/s range: 1°/s = 16.4 LSB
	// In  degrees per second
	MPU_Data.gX = gyro_x / 16.4f;
	MPU_Data.gY = gyro_y / 16.4f;
	MPU_Data.gZ = gyro_z / 16.4f;

}

void readBattery(){//	Converts ADC to battery percentage
	//linear Interpolation to convert ADC to Voltage reading
	float readingVoltage = ( ((float) (ADC_reading - minADC) * (maxVoltage - minVoltage) ) / (maxADC - minADC) ) + minVoltage;

	//Convert to battery percentage
	float batPercentage = ( (readingVoltage - minVoltage) * 100 ) / (maxVoltage - minVoltage);

	ELRS_Data.batteryPercentage = (int)map(batPercentage, 0, 100, ELRSMin, ELRSMax) ;
}

void UGV_setSpeed(TIM_HandleTypeDef *htim, uint32_t channel, int16_t *V_target, uint16_t *V_current){// Sets the UGV speed with P controller

	/*
	  The equation used is discrete proportional (P) controller where:
	  c(t) = k * e(t) * dt + b

	*/

	//float loopTime = 0.001f; // 5ms. This is how fast the speed changes

	float error = *V_target - *V_current;

	//UGV_k = 30.0f -> determines how fast the correction changes

	float acceleration = UGV_k * error;

	*V_current += acceleration * UGV_loopTime + 2; //2 is used as a bias to prevent a zero timer

	__HAL_TIM_SET_COMPARE(htim,channel, *V_current);	//write duty cycle to PWM
}

void UGV_setDirection(GPIO_TypeDef *Port_A, uint16_t Pin_A, GPIO_TypeDef *Port_B, uint16_t Pin_B, int8_t *direction){//	sets the UGV wheel direction with GPIOs
    if (*direction == 1) {
        HAL_GPIO_WritePin(Port_A, Pin_A, GPIO_PIN_SET);
        HAL_GPIO_WritePin(Port_B, Pin_B, GPIO_PIN_RESET);

    } else{
        HAL_GPIO_WritePin(Port_A, Pin_A, GPIO_PIN_RESET);
        HAL_GPIO_WritePin(Port_B, Pin_B, GPIO_PIN_SET);
    }

}

void CRSF_Parser(uint8_t* packet, ELRS_data* input) {//	CRSF parser converts the bytes to individual bits
    uint16_t ch[16];

    // --- MAPPING ---
    // Directly assign if they are already in 172-1811 range
    ch[1] = input->batteryPercentage;

    // Fill unused channels with center value (992)
    for(int i = 1; i < 16; i++) ch[i] = 992;

    // --- STEP 2: PACKET HEADER ---
    packet[0] = 0xC8; // Idenfier for the UV
    packet[1] = 24;   // Length
    packet[2] = 0x16; // Type (RC Channels)

    // --- BIT-PACKING (The 11-bit Squeeze) ---
    // This part never changes, even if struct changes
    packet[3]  = (uint8_t)(ch[0] & 0x07FF);
    packet[4]  = (uint8_t)((ch[0] >> 8) | (ch[1] << 3));
    packet[5]  = (uint8_t)((ch[1] >> 5) | (ch[2] << 6));
    packet[6]  = (uint8_t)(ch[2] >> 2);
    packet[7]  = (uint8_t)((ch[2] >> 10) | (ch[3] << 1));
    packet[8]  = (uint8_t)((ch[3] >> 7) | (ch[4] << 4));
    packet[9]  = (uint8_t)((ch[4] >> 4) | (ch[5] << 7));
    packet[10] = (uint8_t)(ch[5] >> 1);
    packet[11] = (uint8_t)((ch[5] >> 9) | (ch[6] << 2));
    packet[12] = (uint8_t)((ch[6] >> 6) | (ch[7] << 5));
    packet[13] = (uint8_t)(ch[7] >> 3);
    packet[14] = (uint8_t)(ch[8] & 0x07FF);
    packet[15] = (uint8_t)((ch[8] >> 8) | (ch[9] << 3));
    packet[16] = (uint8_t)((ch[9] >> 5) | (ch[10] << 6));
    packet[17] = (uint8_t)(ch[10] >> 2);
    packet[18] = (uint8_t)((ch[10] >> 10) | (ch[11] << 1));
    packet[19] = (uint8_t)((ch[11] >> 7) | (ch[12] << 4));
    packet[20] = (uint8_t)((ch[12] >> 4) | (ch[13] << 7));
    packet[21] = (uint8_t)(ch[13] >> 1);
    packet[22] = (uint8_t)((ch[13] >> 9) | (ch[14] << 2));
    packet[23] = (uint8_t)((ch[14] >> 6) | (ch[15] << 5));
    packet[24] = (uint8_t)(ch[15] >> 3);

    // --- CRC Calculation---
    packet[25] = crsf_crc8(&packet[2], 23);
}

void extractELRS(uint8_t *buf, uint16_t *ch) {//	Extracts the raw ELRS bits to values
    // buf[0] is Address, buf[1] is Length, buf[2] is Type
    // The payload starts at buf[3]

    ch[0]  = ((uint16_t)buf[3]       | (uint16_t)buf[4] << 8)                       & 0x07FF;
    ch[1]  = ((uint16_t)buf[4] >> 3  | (uint16_t)buf[5] << 5)                       & 0x07FF;
    ch[2]  = ((uint16_t)buf[5] >> 6  | (uint16_t)buf[6] << 2 | (uint16_t)buf[7] << 10) & 0x07FF;
    ch[3]  = ((uint16_t)buf[7] >> 1  | (uint16_t)buf[8] << 7)                       & 0x07FF;
    ch[4]  = ((uint16_t)buf[8] >> 4  | (uint16_t)buf[9] << 4)                       & 0x07FF;
    ch[5]  = ((uint16_t)buf[9] >> 7  | (uint16_t)buf[10] << 1 | (uint16_t)buf[11] << 9) & 0x07FF;
    ch[6]  = ((uint16_t)buf[11] >> 2 | (uint16_t)buf[12] << 6)                      & 0x07FF;
    ch[7]  = ((uint16_t)buf[12] >> 5 | (uint16_t)buf[13] << 3)                      & 0x07FF;

    ch[8]  = ((uint16_t)buf[14]      | (uint16_t)buf[15] << 8)                      & 0x07FF;
    ch[9]  = ((uint16_t)buf[15] >> 3 | (uint16_t)buf[16] << 5)                      & 0x07FF;
    ch[10] = ((uint16_t)buf[16] >> 6 | (uint16_t)buf[17] << 2 | (uint16_t)buf[18] << 10) & 0x07FF;
    ch[11] = ((uint16_t)buf[18] >> 1 | (uint16_t)buf[19] << 7)                      & 0x07FF;
    ch[12] = ((uint16_t)buf[19] >> 4 | (uint16_t)buf[20] << 4)                      & 0x07FF;
    ch[13] = ((uint16_t)buf[20] >> 7 | (uint16_t)buf[21] << 1 | (uint16_t)buf[22] << 9) & 0x07FF;
    ch[14] = ((uint16_t)buf[22] >> 2 | (uint16_t)buf[23] << 6)                      & 0x07FF;
    ch[15] = ((uint16_t)buf[23] >> 5 | (uint16_t)buf[24] << 3)                      & 0x07FF;

    //Takes ~112 Cycles. For 168MHz, about 666ns. via AI
}

uint8_t crsf_crc8(uint8_t *ptr, uint8_t len) {//	Compute CRC for ELRS
	uint8_t crc = 0;
	    while (len--) {
	        crc = crsf_crc8_table[crc ^ *ptr++];
	    }
	    return crc;
}

uint8_t bitMask(uint16_t ch1){//	Decomposes the bits of channel 1 via bit masking
	UGV_Controls.leftMotor_Dir 	 = ch1 & 1;
	UGV_Controls.rightMotor_Dir  = (ch1 >> 1) & 1;
	cameraMove					 = (ch1 >> 2) & 1;
	calibrationMode				 = (ch1 >> 3) & 1;

	return	(ch1 >> 9) & 1;
}

void DSHOT_PreparePacket(uint16_t throttle, uint8_t motorNumber, uint8_t stop_button, uint8_t request_telemetry) {//		Receives dshot values
	//This whole function takes ~4.5us

	// 1. Handle Stop Button vs Active Range
    if (stop_button) {
        dshot_value = 0; // Absolute stop/disarm
    }
    else {
        // Clamp input to 0-1999 to prevent overflow
        if (throttle > 1999) throttle = 1999;
        dshot_value = throttle + 48;
    }

    // 2. Assemble 12-bit packet (11 bits throttle + 1 bit telemetry)
    DSHOT_packet = (dshot_value << 1) | (request_telemetry ? 1 : 0);     // Shift left 1, then OR with the telemetry bit (1 if requested, 0 if not)

    // 3. Calculate 4-bit CRC
    // XOR the three 4-bit nibbles of the 12-bit packet
    uint16_t crc = (DSHOT_packet ^ (DSHOT_packet >> 4) ^ (DSHOT_packet >> 8)) & 0x0F;

    // 4. Final 16-bit frame (Shift packet left by 4, then add CRC)
    DSHOT_packet = (DSHOT_packet << 4) | crc;

    // 5. Slice the 16-bit packet into 16 physical PWM duty cycle values
    for (int i = 0; i < 16; i++) {
    	// Test the bit at the current position (starting from MSB)
    	if (DSHOT_packet & (0x8000 >> i)) {
    		dma_buffer[motorNumber][i] = DSHOT_1; // Send a 1
    	}
    	else {
    		dma_buffer[motorNumber][i] = DSHOT_0; // Send a 0
            }
    }

    // 6. Append the reset pulses to pull the PWM line LOW at the end
    dma_buffer[motorNumber][16] = 0;
    dma_buffer[motorNumber][17] = 0;
}

void DSHOT_Fire() {//	Turns the DSHOT values to PWM
	//This whole function takes ~6 - 8us
	// Cycle through all 4 motors and trigger their DMA streams
    for (int i = 0; i < 4; i++) {
        // HAL_TIM_PWM_Start_DMA automatically enables the timer counter,
        // the PWM output on the pin, and the DMA request.
        HAL_TIM_PWM_Start_DMA(&htim3, timer_channels[i], (uint32_t *)dma_buffer[i], 18);
    }
}

void complementaryFilter(){//	Filter noise vibrations from the MPU readings
	//This whole function takes ~1.7 - 2us

	float Raw_Roll_Angle = atan2f(MPU_Data.aY, MPU_Data.aZ) * RAD_TO_DEG;

	float magnitude =  sqrtf((MPU_Data.aY * MPU_Data.aY) + (MPU_Data.aZ * MPU_Data.aZ));

	float Raw_Pitch_Angle = atan2f(-MPU_Data.aZ, magnitude) * RAD_TO_DEG;

	/* Because all are float the FPU of the STM32 is utilized so it will be faster
	 * atan2f() takes about 70-120 cycles
	 * Overall upto this point the code takes about 250 - 300 cycles --> 1.5 - 1.8 us
	 */

	Filtered_Roll_Angle = (filter_Alpha *(Last_Filtered_Roll_Angle + (MPU_Data.gX * UAV_loopTime) ) ) + ( (filter_Beta) * Raw_Roll_Angle);

	Filtered_Pitch_Angle = (filter_Alpha *(Last_Filtered_Pitch_Angle + (MPU_Data.gY * UAV_loopTime) ) ) + ( (filter_Beta) * Raw_Pitch_Angle);

	Last_Filtered_Roll_Angle  = Filtered_Roll_Angle;
	Last_Filtered_Pitch_Angle = Filtered_Pitch_Angle;
	// From the 2nd Half it will take ~40 cycles	--> .24us

}

void UAV_error(){//	Computes the errors of the angles
	/* This part is the Outer PID
	 *
	 * This takes about 50 cycles --> 297.5 ns
	 */
	float Rate_Roll_Target = K_outer * (Roll - Filtered_Roll_Angle);
	float Rate_Pitch_Target = K_outer * (Pitch - Filtered_Pitch_Angle);
	float Rate_Yaw_Target = Yaw;

	RollError = Rate_Roll_Target - MPU_Data.gX;
	PitchError = Rate_Pitch_Target - MPU_Data.gY;
	YawError = Rate_Yaw_Target - MPU_Data.gZ;

}

void UAV_PID(float *Total, float error, float *last_I, float gyro, float *last_gyro){ // format: Axis(Roll,Pitch,Yaw) , error , last integral , Current gyro axis reading , last gyro axis reading
	//This whole function takes ~1.5us

	float Proportional = Kp_inner * massRatio * error;
	float Integral = *last_I + (Ki_inner * massRatio * error * UAV_loopTime);
	float Derivative = -Kd_inner * massRatio * ( (gyro - *last_gyro)* UAV_loopTime_INV);

	*Total = fmax(-Lim, fmin(Proportional + Integral + Derivative , Lim) );
	*last_gyro = gyro;
	*last_I = Integral;

}

void UAV_convertThrust(){
	//This whole function takes ~1.5us

	if(rawThrust >= ELRS_higherDeadZone){//ELRS received joystick value above the middle
		rawThrust = map(rawThrust, ELRS_higherDeadZone, ELRSMax, 1001, DSHOTmax);
		Thrust = Calibrated_Hover + (DSHOTmax - Calibrated_Hover) * ( (rawThrust - DSHOTcenter) / 999.0f);
	}
	else{//ELRS received joystick value below the middle
		rawThrust = map(rawThrust, ELRSMin, 991, 0, DSHOTcenter);
		Thrust = Calibrated_Hover * (rawThrust / DSHOTcenter);
	}
}

void UAV_normalizeMotor(){
	//This whole function takes ~1.8us

	Total_Thrust = Thrust / (cos(Filtered_Pitch_Angle) * cos(Filtered_Roll_Angle));

	M1raw = Total_Thrust - Total_Roll - Total_Pitch + Total_Yaw;
	M2raw = Total_Thrust + Total_Roll - Total_Pitch - Total_Yaw;
	M3raw = Total_Thrust + Total_Roll + Total_Pitch + Total_Yaw;
	M4raw = Total_Thrust - Total_Roll + Total_Pitch - Total_Yaw;

	float M_max = fmax(fmax(M1raw, M2raw), fmax(M3raw, M4raw));
	float M_min = fmin(fmin(M1raw, M2raw), fmin(M3raw, M4raw));

	float Motor_Diff = M_max - M_min;
	if(Motor_Diff > M_max ){
		M1raw = Total_Thrust + (M1raw - Total_Thrust) * (Rotmax / Motor_Diff);
		M2raw = Total_Thrust + (M2raw - Total_Thrust) * (Rotmax / Motor_Diff);
		M3raw = Total_Thrust + (M3raw - Total_Thrust) * (Rotmax / Motor_Diff);
		M4raw = Total_Thrust + (M4raw - Total_Thrust) * (Rotmax / Motor_Diff);
	}

	float overflowTop = fmax(0, M_max - Rotmax);
	float overflowBot = fmax(0, 0 - M_min);

	Motor1 = M1raw - overflowTop + overflowBot;
	Motor2 = M2raw - overflowTop + overflowBot;
	Motor3 = M3raw - overflowTop + overflowBot;
	Motor4 = M4raw - overflowTop + overflowBot;
}

void UAV_convertTilt(float rawAxis, float *Axis){//	Converts Roll and Pitch to degrees
	//This whole function takes ~1.5us

	//This is called ternary operation
	int8_t direction = (rawAxis > ELRS_higherDeadZone) ? 1 : (rawAxis < ELRS_lowerDeadZone) ? -1 : 0;

	if (direction == 1 ){//	Above the middle, so a positive angle
		*Axis	= map(rawAxis, ELRS_higherDeadZone, ELRSMax, minTilt, maxTilt);
	}

	else if (direction == -1 ){//	below the middle, so a negative angle
		*Axis	= -map(rawAxis, ELRSMin, ELRS_lowerDeadZone, maxTilt, minTilt);
	}
	else{
		*Axis = 0;
	}

}

void UAV_convertYaw(float rawAxis, float *Axis){//	Converts Yaw to degrees/second
	//This whole function takes ~1.5us

	//This is called ternary operation
	int8_t direction = (rawAxis > ELRS_higherDeadZone) ? 1 : (rawAxis < ELRS_lowerDeadZone) ? -1 : 0;

	if (direction == 1 ){//	Above the middle, so a positive angle
		*Axis	= map(rawAxis, ELRS_higherDeadZone, ELRSMax, minYaw, maxYaw);
	}

	else if (direction == -1 ){//	below the middle, so a negative angle
		*Axis	= -map(rawAxis, ELRSMin, ELRS_lowerDeadZone, maxYaw, minYaw);
	}
	else{
		*Axis = 0;
	}

}

//---------------------------------------------------------------------------------------------- ISR Functions-------------------------------------------------------------------------------------------------------------------

void HAL_UART_RxCpltCallback(UART_HandleTypeDef *huart) {//	ISR when UART receives something
    if (huart->Instance == UART4) {//	Checks if UART4

    	if(UAVloop){//Prevents the ELRS from changing the data when PID loop is ongoing
    		return;
    	}

    	ELRS_buffer[rx_index++] = rx_byte;

        // 1. Check for Sync Byte (Address)
        if (ELRS_buffer[0] != 0xC8 && ELRS_buffer[0] != 0xEE) {
            rx_index = 0;
        }
        // 2. Check if we have a full packet (Header 2 bytes + Payload 24 bytes)
        else if (rx_index >= 26) {
            // Verify CRC
            uint8_t computed_crc = crsf_crc8(&ELRS_buffer[2], 23);

            if (computed_crc == ELRS_buffer[25]) {
            	extractELRS(ELRS_buffer, channels);
                // Map to variables
            	uint8_t mode = bitMask(channels[0]);
            	if (mode){//	UAV
                    cameraAngle_X = channels[1] - 172;	//deducts the 172 added by the controller
                    cameraAngle_Y = channels[2] - 172;
                    rawRoll 		  = channels[3];
                    rawPitch 		  = channels[4];
                    rawYaw 			  = channels[5];
                    rawThrust 		  = channels[6];
            	}
            	else{//	UGV
                    cameraAngle_X = channels[1] - 172;	//deducts the 172 added by the controller
                    cameraAngle_Y = channels[2] - 172;
                    UGV_Controls.rightMotor    = channels[3];
                    UGV_Controls.leftMotor	   = channels[4];
            	}
            }
            // Reset index for next packet
            rx_index = 0;
        }
        // IMPORTANT: Re-enable the interrupt for the next byte
        HAL_UART_Receive_IT(&huart4, &rx_byte, 1);
    }
}

void HAL_TIM_PeriodElapsedCallback(TIM_HandleTypeDef *htim){//	Gets called whenever there is an overflow on any timer

	//This is wrong. TIM4 has been moved for the servo
	if (htim->Instance == TIM4){//	Checks if timer overflow is Timer 4
       //ISR every 5ms
		if (UV_MODE)return;	//	If not UGV return
    	UGV_setDirection(GPIOC, GPIO_PIN_6, GPIOA, GPIO_PIN_7, &UGV_Controls.leftMotor_Dir);
    	UGV_setDirection(GPIOE, GPIO_PIN_11, GPIOE, GPIO_PIN_9, &UGV_Controls.rightMotor_Dir);

    	UGV_setSpeed(&htim1, TIM_CHANNEL_3, &UGV_Controls.leftMotor, &UGV_leftVelocity);
    	UGV_setSpeed(&htim1, TIM_CHANNEL_4, &UGV_Controls.rightMotor, &UGV_rightVelocity);

    }
}

void HAL_RTCEx_WakeUpTimerEventCallback(RTC_HandleTypeDef *hrtc){//	LSE Timer ISR
/*
 * Sampling time is calculated by:
 *
 * ADC clock = APB2 / prescaler		--> 84MHz / 4 = 21MHz
 * Conversion time = Sampling time + Conversion time for bits(12.5 cycles for 12bit)	--> 144 Cycles + 12.5 Cycles = 156.5 Cycles
 * Cycle = 1 / ADC clock	--> 1 / 21MHz = 47.619ns
 * Sampling time = Conversion time * Cycle		-->	47.619ns * 156.5 cycles	= 7.452us per sample
 *
 * Make sure that an ISR is always below 50% time than the interrupt
 * It takes 7.452us * 4096 = 30.523ms for the buffer to be full
 */

	ADCsum = 0;	//resets the sum after evry call
	for (uint16_t i = 0; i <= 4095; i ++){
		ADCsum += ADC_buffer[i];
	}
	ADC_reading = ADCsum>>12;	// to make this faster use bitshift instead because 4096 is 2^n. this is same as ADCsum/4096

/*
 * loop checking	 = 5.95ns
 * access array		 = 11.90ns
 * addition			 = 5.95ns
 * loop cycle		 = 23.8ns
 * loop completion	 = 23.8ns * 4096 = 97.485us
 * division			 = 5.95ns
 * total time		 = 97.491us
 */

}

void HAL_GPIO_EXTI_Callback(uint16_t GPIO_Pin){//	EXTI ISR
	if(GPIO_Pin == IMU_INT_Pin){
		//error+=1;
		MPUstatus = 1;	//Set to a volatile variable instead of reading MPU directly to prevent a blocking
	}
}

void HAL_TIM_PWM_PulseFinishedCallback(TIM_HandleTypeDef *htim) {// This function is automatically triggered by the hardware DMA Interrupt

	//For DSHOT
    if (htim->Instance == TIM3) {// 1. Verify that the interrupt came from Timer 3

        // 2. Check WHICH channel just finished, and stop ONLY its DMA stream.
        // We use HAL_TIM_ACTIVE_CHANNEL_x here because the HAL uses a different
        // naming convention inside the interrupt status register.

        if (htim->Channel == HAL_TIM_ACTIVE_CHANNEL_1) {
            HAL_TIM_PWM_Stop_DMA(htim, TIM_CHANNEL_1);
        }
        else if (htim->Channel == HAL_TIM_ACTIVE_CHANNEL_2) {
            HAL_TIM_PWM_Stop_DMA(htim, TIM_CHANNEL_2);
        }
        else if (htim->Channel == HAL_TIM_ACTIVE_CHANNEL_3) {
            HAL_TIM_PWM_Stop_DMA(htim, TIM_CHANNEL_3);
        }
        else if (htim->Channel == HAL_TIM_ACTIVE_CHANNEL_4) {
            HAL_TIM_PWM_Stop_DMA(htim, TIM_CHANNEL_4);
        }
    }
}

/* USER CODE END 4 */

void Error_Handler(void)
{
  /* USER CODE BEGIN Error_Handler_Debug */
  /* User can add his own implementation to report the HAL error return state */

 // __disable_irq();	//This thing disables the sytem tick so blinking LED doesnt work

  while (1)
  {
/*
	    // Blink error times
	    for (uint8_t i = 0; i < error; i++)
	    {
	        HAL_GPIO_WritePin(GPIOA, GPIO_PIN_8, GPIO_PIN_SET);
	        HAL_Delay(500);

	        HAL_GPIO_WritePin(GPIOA, GPIO_PIN_8, GPIO_PIN_RESET);
	        HAL_Delay(500);
	    }

	    // Remaining idle time
	    for (uint8_t i = error; i < errorMax; i++)
	    {
	        HAL_Delay(500);
	    }

	     */
  }
  /* USER CODE END Error_Handler_Debug */
}
